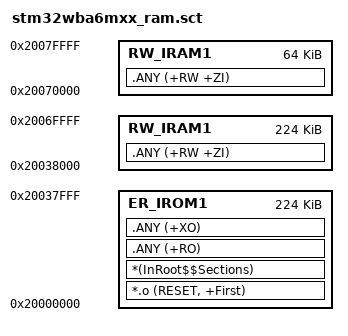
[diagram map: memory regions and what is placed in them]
; *************************************************************
; *** Scatter-Loading Description File generated by uVision ***
; *************************************************************

LR_IROM1 0x20000000 0x00038000  {    ; load region size_region
  ER_IROM1 0x20000000 0x00038000  {  ; load address = execution address
   *.o (RESET, +First)
   *(InRoot$$Sections)
   .ANY (+RO)
   .ANY (+XO)
  }
  RW_IRAM1 0x20038000 0x00038000  {  ; RW data
   .ANY (+RW +ZI)
  }
  RW_IRAM1 0x20070000 0x00010000  {  ; RW data
   .ANY (+RW +ZI)
  }
}

